# ATA8515 device description
Architecture: AVR8; Family: megaAVR
Registers are 8-bit, access not given, no defined reset value unless marked. A register's access mark holds for its fields unless they carry their own. Offsets are from the block's base; [hi:lo] are bit positions; {n}, {i} and the like mark numbered series.

## FE
Instances: FE 0x00
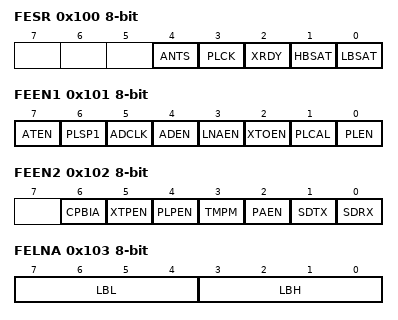
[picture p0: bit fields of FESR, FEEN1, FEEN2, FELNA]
0x100 FESR — Front-End Status Register
  [4] ANTS — Antenna saturated
  [3] PLCK — PLL locked
  [2] XRDY — XTO ready
  [1] HBSAT — LNA High band saturated
  [0] LBSAT — LNA Low band saturated
0x101 FEEN1 — Front-End Enable Register 1
  [7] ATEN — Antenna Tuning Enable
  [6] PLSP1 — PLL Speedup 1
  [5] ADCLK — ADC Clock enable
  [4] ADEN — Analog Digital Converter enable
  [3] LNAEN — Low Noise Amplifier enable
  [2] XTOEN — Cristal Oscillator enable
  [1] PLCAL — PLL calibration mode
  [0] PLEN — PLL enable
0x102 FEEN2 — Front-End Enable Register 2
  [6] CPBIA — Cap Array Bias
  [5] XTPEN — XTO VPump enable
  [4] PLPEN — PLL Post En IQ divider
  [3] TMPM — Temperature measurement
  [2] PAEN — Power Amplifier enable
  [1] SDTX — Single Pole Double Throw (SPDT) Switch TX
  [0] SDRX — Single Pole Double Throw (SPDT) Switch RX
0x103 FELNA — Front-End LNA Bias Register
  [7:4] LBL — LNA Bias Low band
  [3:0] LBH — LNA Bias High band
0x104 FEAT — Front-End Antenna Tuning
  [3:0] ANTN — Antenna Tuning
0x105 FEPAC — Front-End Power Amplifier Control Register Pout/dBm LowBand HighBand
0x106 FEVCT — Front-End VCO Tuning Register
  [3:0] FEVCT
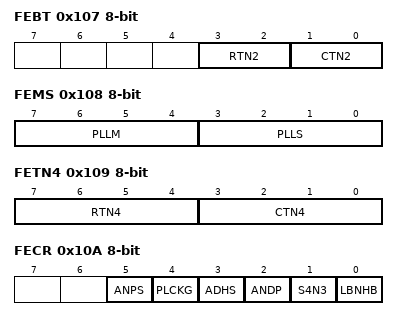
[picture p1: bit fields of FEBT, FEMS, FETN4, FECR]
0x107 FEBT — Front-End RC Tuning Register
  [3:2] RTN2 — Resistor Tuning
  [1:0] CTN2 — Capacitor Tuning
0x108 FEMS — Front-End Main and Swallow Control Register
  [7:4] PLLM — PLL Mode
  [3:0] PLLS — PLL Swallow
0x109 FETN4 — Front-End RC Tuning 4bit Register
  [7:4] RTN4 — 4 bit Resistor Tuning
  [3:0] CTN4 — 4 bit Capacitor Tuning
0x10A FECR — Front-End Control Register
  [5] ANPS — ASK Not DPSK Switch
  [4] PLCKG — PLL Lock Detect Gate
  [3] ADHS — ADC High Sample Rate
  [2] ANDP — Antenna Damping
  [1] S4N3 — Select 433 Not 315MHz Band
  [0] LBNHB — Select Low-Band Not High-Band
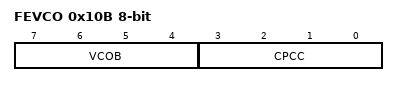
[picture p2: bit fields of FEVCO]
0x10B FEVCO — Front-End VCO and PLL control
  [7:4] VCOB — VCO Bias
  [3:0] CPCC — Charge pump current control
0x10C FEALR — Front-End Antenna Level Detector Range
  [1:0] RNGE — Range of the ANT_TUNE level detector
    0=0..3 dBm; 1=4..7 dBm; 2=8..14 dBm; 3=Secure Measurement
0x10D FEANT — Front-End ANTenna
  [3:0] LVLC — antenna signal LeVeL
0x10E FEBIA — Front-End IF Amplifier BIAS
  [7] IFAEN — IF Amplifier Enable
Value list FE_POWER_AMPLIFIER_CONTROL: 0=-11.80 -12.90; 1=-11.30 -12.33; 2=-10.70 -11.76; 3=-10.20 -11.10; 4=-9.70 -10.60; 5=-9.20 -10.00; 6=-8.60 -9.50; 7=-8.00 -9.00; 8=-7.50 -8.50; 9=-7.00 -7.90; 10=-6.40 -7.30; 11=-5.90 -6.80; 12=-5.30 -6.30; 13=-4.77 -5.70; 14=-4.17 -5.20; 15=-3.67 -4.60; 16=-3.12 -4.07; 17=-2.56 -3.47; 18=-2.10 -2.97; 19=-1.58 -2.42; 20=-1.08 -1.86; 21=-0.50 -1.40; 22=0.00 -0.88; 23=0.41 -0.38; 24=1.00 0.20; 25=1.42 0.70; 26=1.83 1.11; 27=2.42 1.70; 28=2.88 2.12; 29=3.38 2.53; 30=3.81 3.12; 31=4.31 3.58; 32=4.72 4.08; 33=5.09 4.51; 34=5.57 5.01; 35=6.00 5.42; 36=6.41 5.79; 37=6.77 6.27; 38=7.19 6.70; 39=7.55 7.11; 40=7.98 7.47; 41=8.40 7.89; 42=8.79 8.25; 43=9.11 8.68; 44=9.46 9.10; 45=9.82 9.49; 46=10.18 9.81; 47=10.60 10.16; 48=10.89 10.52; 49=11.30 10.88; 50=11.62 11.30; 51=12.06 11.59; 52=12.39 12.00; 53=12.82 12.32; 54=13.22 12.76; 55=13.58 13.09; 56=13.95 13.52; 57=14.22 13.92; 58=14.41 14.28; 59=14.49 14.65; {v}=14.60 14.65 (v=60..63)

## FREQS
Instances: FREQS 0x00
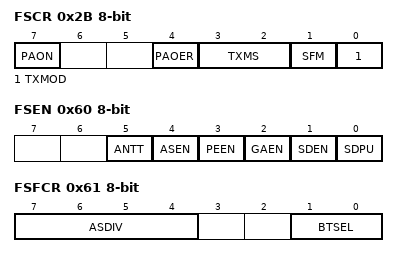
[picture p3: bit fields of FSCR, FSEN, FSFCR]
0x2B FSCR — Frequency Synthesizer Control Register
  [7] PAON — Power Amplifier Output is On
  [4] PAOER — Power Amplifier Output Enable Register
  [3:2] TXMS — Tx Modulation Source
    0=TXMOD Register; 1=TMDI Input; 2=Tx Modulator Serial Out
  [1] SFM — Select FSK Modulation
  [0] TXMOD — Tx Modulation
0x60 FSEN — Frequency Synthesizer Enable register
  [5] ANTT — Antenna Tuning Active
  [4] ASEN — ASK Shaping Enable
  [3] PEEN — Pre-emphasis Filtering Enable
  [2] GAEN — Gauss Filtering Enable
  [1] SDEN — Sigma-delta Modulator Enable
  [0] SDPU — Sigma-delta Modulator Power Up
0x61 FSFCR — Frequency Synthesizer Filter Control Register
  [7:4] ASDIV — ASK Shaping Divider
  [1:0] BTSEL — Gauss Filter BT Selection
0x62 GACDIV 16-bit bits used 12:0 — Gauss Clock Divider
0x64 FFREQ1L — Fractional Frequency 1 Setting, Low Byte
0x65 FFREQ1M — Fractional Frequency 1 Setting, Middle Byte
0x66 FFREQ1H bits used 1:0 — Fractional Frequency 1 Setting, High Byte
0x67 FFREQ2L — Fractional Frequency 2 Setting, Low Byte
0x68 FFREQ2M — Fractional Frequency 2 Setting, Middle Byte
0x69 FFREQ2H bits used 1:0 — Fractional Frequency 2 Setting, High Byte
